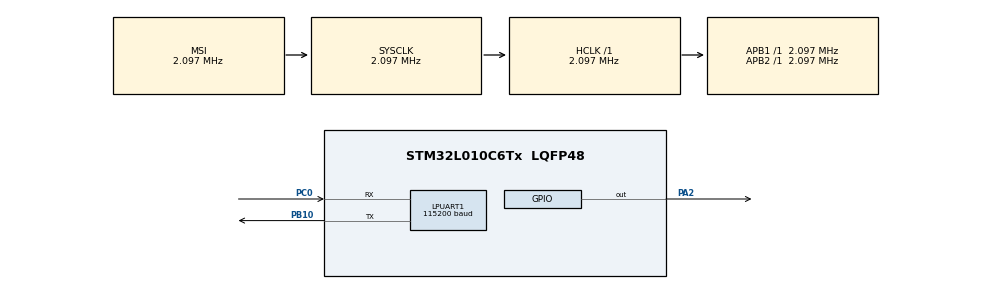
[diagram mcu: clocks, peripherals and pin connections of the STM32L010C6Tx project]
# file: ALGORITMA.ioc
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LPUART1.BaudRate=115200
LPUART1.WordLength=UART_WORDLENGTH_8B
Mcu.Family=STM32L0
Mcu.Name=STM32L010C6Tx
Mcu.Package=LQFP48
PA13.Mode=Serial_Wire
PA13.Signal=SYS_SWDIO
PA14.Mode=Serial_Wire
PA14.Signal=SYS_SWCLK
PA2.Signal=GPIO_Output
PB10.Mode=Asynchronous
PB10.Signal=LPUART1_TX
PC0.Mode=Asynchronous
PC0.Signal=LPUART1_RX
ProjectManager.HeapSize=0x200
ProjectManager.StackSize=0x400
ProjectManager.TargetToolchain=STM32CubeIDE
RCC.AHBFreq_Value=2097000
RCC.APB1Freq_Value=2097000
RCC.APB1TimFreq_Value=2097000
RCC.APB2Freq_Value=2097000
RCC.APB2TimFreq_Value=2097000
RCC.HSE_VALUE=8000000
RCC.HSI16_VALUE=16000000
RCC.HSI_VALUE=16000000
RCC.LSE_VALUE=32768
RCC.MSI_VALUE=2097000
RCC.SYSCLKFreq_VALUE=2097000
RCC.VCOOutputFreq_Value=48000000
board=custom

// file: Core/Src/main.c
/**
 @Adi: Zahide Zeynep
 @Soyadi: Kurt
 @Tarih: 11.05.2022
 @Ciktilar:
Örnek dizide çarpımları en büyük sonucu veren 13 ardışık rakam:
9x7x8x1x7x9x7x7x8x4x6x1x7= 2091059712 'dir.
Bu 13 rakamın  dizi içindeki konumu 504 ile başlayıp 516 ile bitmektedir

Örnek dizide çarpımları en büyük sonucu veren 14 ardışık rakam:
6x5x4x5x6x8x2x8x4x8x9x1x2x8= 2123366400 'dir.
Bu 14 rakamın  dizi içindeki konumu 723 ile başlayıp 736 ile bitmektedir

Örnek dizide çarpımları en büyük sonucu veren 15 ardışık rakam:
6x5x4x5x6x8x2x8x4x8x9x1x2x8x8= 2123366400 'dir.
Bu 15 rakamın  dizi içindeki konumu 723 ile başlayıp 737 ile bitmektedir
 ...
 */

/* USER CODE BEGIN Header */
/**
 ******************************************************************************
 * @file           : main.c
 * @brief          : Main program body
 ******************************************************************************
 * @attention
 *
 * <h2><center>&copy; Copyright (c) 2022 STMicroelectronics.
 * All rights reserved.</center></h2>
 *
 * This software component is licensed by ST under BSD 3-Clause license,
 * the "License"; You may not use this file except in compliance with the
 * License. You may obtain a copy of the License at:
 *                        opensource.org/licenses/BSD-3-Clause
 *
 ******************************************************************************
 */
/* USER CODE END Header */
#include "main.h"

/* USER CODE BEGIN Includes */
#include <string.h>
#include <stdio.h>
#include <stdlib.h>
#define printf(...)  HAL_UART_Transmit((UART_HandleTypeDef *)&hlpuart1, (uint8_t *)u_buf,\
		                                sprintf((char*)u_buf,__VA_ARGS__), 0xFFFF);
uint8_t u_buf[256];

/* USER CODE END Includes */

UART_HandleTypeDef hlpuart1;

void SystemClock_Config(void);
static void MX_GPIO_Init(void);
static void MX_LPUART1_UART_Init(void);

/* USER CODE BEGIN 0 */
#define ElemanSayisi 1000 //* Program herhangi bir X elemanlı herhangi bir diziye uygun olarak yazılmıştır. Buffer uzunluğunun her yerden kolayca değiştirilebilmesi için buffer uzunluğunu #define ile tanımlarız.
uint8_t buffer[ElemanSayisi] =
		{ 6, 4, 0, 7, 7, 1, 7, 6, 5, 3, 1, 3, 3, 0, 6, 2, 4, 9, 1, 9, 2, 2, 5,
				1, 1, 9, 6, 7, 4, 4, 2, 6, 5, 7, 4, 7, 4, 2, 3, 5, 5, 3, 4, 9,
				1, 9, 4, 9, 3, 4, 9, 6, 9, 8, 3, 5, 2, 0, 3, 1, 2, 7, 7, 4, 5,
				0, 6, 3, 2, 6, 2, 3, 9, 5, 7, 8, 3, 1, 8, 0, 1, 6, 9, 8, 4, 8,
				0, 1, 8, 6, 9, 4, 7, 8, 8, 5, 1, 8, 4, 3, 8, 5, 8, 6, 1, 5, 6,
				0, 7, 8, 9, 1, 1, 2, 9, 4, 9, 4, 9, 5, 4, 5, 9, 5, 0, 1, 7, 3,
				7, 9, 5, 8, 3, 3, 1, 9, 5, 2, 8, 5, 3, 2, 0, 8, 8, 0, 5, 5, 1,
				1, 1, 2, 5, 4, 0, 6, 9, 8, 7, 4, 7, 1, 5, 8, 5, 2, 3, 8, 6, 3,
				0, 5, 0, 7, 1, 5, 6, 9, 3, 2, 9, 0, 9, 6, 3, 2, 9, 5, 2, 2, 7,
				4, 4, 3, 0, 4, 3, 5, 5, 7, 6, 6, 8, 9, 6, 6, 4, 8, 9, 5, 0, 4,
				4, 5, 2, 4, 4, 5, 2, 3, 1, 6, 1, 7, 3, 1, 8, 5, 6, 4, 0, 3, 0,
				9, 8, 7, 1, 1, 1, 2, 1, 7, 2, 2, 3, 8, 3, 1, 1, 3, 6, 2, 2, 2,
				9, 8, 9, 3, 4, 2, 3, 3, 8, 0, 3, 0, 8, 1, 3, 5, 3, 3, 6, 2, 7,
				6, 6, 1, 4, 2, 8, 2, 8, 0, 6, 4, 4, 4, 4, 8, 6, 6, 4, 5, 2, 3,
				8, 7, 4, 9, 3, 0, 3, 5, 8, 9, 0, 7, 2, 9, 6, 2, 9, 0, 4, 9, 1,
				5, 6, 0, 4, 4, 0, 7, 7, 2, 3, 9, 0, 7, 1, 3, 8, 1, 0, 5, 1, 5,
				8, 5, 9, 3, 0, 7, 9, 6, 0, 8, 6, 6, 7, 0, 1, 7, 2, 4, 2, 7, 1,
				2, 1, 8, 8, 3, 9, 9, 8, 7, 9, 7, 9, 0, 8, 7, 9, 2, 2, 7, 4, 9,
				2, 1, 9, 0, 1, 6, 9, 9, 7, 2, 0, 8, 8, 8, 0, 9, 3, 7, 7, 6, 6,
				5, 7, 2, 7, 3, 3, 3, 0, 0, 1, 0, 5, 3, 3, 6, 7, 8, 8, 1, 2, 2,
				0, 2, 3, 5, 4, 2, 1, 8, 0, 9, 7, 5, 1, 2, 5, 4, 5, 4, 0, 5, 9,
				4, 7, 5, 2, 2, 4, 3, 5, 2, 5, 8, 4, 9, 0, 7, 7, 1, 1, 6, 7, 0,
				5, 5, 6, 0, 1, 3, 6, 0, 4, 8, 3, 9, 5, 8, 6, 4, 4, 6, 7, 0, 6,
				3, 2, 4, 4, 1, 5, 7, 2, 2, 1, 5, 5, 3, 9, 7, 5, 3, 6, 9, 7, 8,
				1, 7, 9, 7, 7, 8, 4, 6, 1, 7, 4, 0, 6, 4, 9, 5, 5, 1, 4, 9, 2,
				9, 0, 8, 6, 2, 5, 6, 9, 3, 2, 1, 9, 7, 8, 4, 6, 8, 6, 2, 2, 4,
				8, 2, 8, 3, 9, 7, 2, 2, 4, 1, 3, 7, 5, 6, 5, 7, 0, 5, 6, 0, 5,
				7, 4, 9, 0, 2, 6, 1, 4, 0, 7, 9, 7, 2, 9, 6, 8, 6, 5, 2, 4, 1,
				4, 5, 3, 5, 1, 0, 0, 4, 7, 4, 8, 2, 1, 6, 6, 3, 7, 0, 4, 8, 4,
				4, 0, 3, 1, 3, 9, 8, 9, 0, 0, 0, 8, 8, 9, 5, 2, 4, 3, 4, 5, 0,
				6, 5, 8, 5, 4, 1, 2, 2, 7, 5, 8, 8, 6, 6, 6, 8, 8, 1, 1, 6, 4,
				2, 7, 1, 7, 1, 4, 7, 9, 9, 2, 4, 4, 4, 2, 9, 2, 8, 2, 3, 0, 8,
				6, 3, 4, 6, 5, 6, 7, 4, 8, 1, 3, 9, 1, 9, 1, 2, 3, 1, 6, 2, 8,
				2, 4, 5, 8, 6, 1, 7, 8, 6, 6, 4, 5, 8, 3, 5, 9, 1, 2, 4, 5, 6,
				6, 5, 2, 9, 4, 7, 6, 5, 4, 5, 6, 8, 2, 8, 4, 8, 9, 1, 2, 8, 8,
				3, 1, 4, 2, 6, 0, 7, 6, 9, 0, 0, 4, 2, 2, 4, 2, 1, 9, 0, 2, 2,
				6, 7, 1, 0, 5, 5, 6, 2, 6, 3, 2, 1, 1, 1, 1, 1, 0, 9, 3, 7, 0,
				5, 4, 4, 2, 1, 7, 5, 0, 6, 9, 4, 1, 6, 5, 8, 9, 6, 0, 4, 0, 8,
				0, 7, 1, 9, 8, 4, 0, 3, 8, 5, 0, 9, 6, 2, 4, 5, 5, 4, 4, 4, 3,
				6, 2, 9, 8, 1, 2, 3, 0, 9, 8, 7, 8, 7, 9, 9, 2, 7, 2, 4, 4, 2,
				8, 4, 9, 0, 9, 1, 8, 8, 8, 4, 5, 8, 0, 1, 5, 6, 1, 6, 6, 0, 9,
				7, 9, 1, 9, 1, 3, 3, 8, 7, 5, 4, 9, 9, 2, 0, 0, 5, 2, 4, 0, 6,
				3, 6, 8, 9, 9, 1, 2, 5, 6, 0, 7, 1, 7, 6, 0, 6, 0, 5, 8, 8, 6,
				1, 1, 6, 4, 6, 7, 1, 0, 9, 4, 0, 5, 0, 7, 7, 5, 4, 1, 0, 0, 2,
				2, 5, 6, 9, 8, 3, 1, 5, 5, 2, 0, 0, 0, 5, 5, 9, 3, 5, 7, 2, 9,
				7, 2, 5, 7, 1, 6, 3, 6, 2, 6, 9, 5, 6, 1, 8, 8, 2, 6, 7, 0, 4,
				2, 8, 2, 5, 2, 4, 8, 3, 6, 0, 0, 8, 2, 3, 2, 5, 7, 5, 3, 0, 4,
				2, 0, 7, 5, 2, 9, 6, 3, 4, 5, 0, };

uint8_t *arr = (uint8_t*) &buffer; // Buffer adresini gösteren bir pointer arr oluşturduk.
// Program çıktısında istenilen çarpım sonucu ve başlangıç konumu tutacak global ifadeler tanımlanır.
int geciciIndex = 0, geciciCarpim = 0;
int Index, carpim, baslangic, bitis;
/* USER CODE END 0 */

int main(void) {

	/* MCU Configuration--------------------------------------------------------*/

	/* Reset of all peripherals, Initializes the Flash interface and the Systick. */
	HAL_Init();

	/* Configure the system clock */
	SystemClock_Config();

	/* Initialize all configured peripherals */
	MX_GPIO_Init();
	MX_LPUART1_UART_Init();
	int enbuyukcarpim(uint8_t *arr, int carpilacaksayi); //Aşağıda enbuyukcarpim adında bir fonksiyon oluşturulmuştur ve bu fonksiyon burada tanımlanır. Başındaki int, integer bir değer döndürdüğü anlamına gelir.
	int maxSayi = enbuyukcarpim(buffer, 13); //enbuyukcarpim foksiyonunun içine yukarıda tanılmış buffer ve kaç adet sayının çarpılmasını istiyorsak onu gönderiyoruz. burada fonksiyondan dönen sonucu MaxSayi içine atıyoruz.
	maxSayi = enbuyukcarpim(buffer, 14);
	maxSayi = enbuyukcarpim(buffer, 15);
	/* Infinite loop */
	while (1) {

	}
}

void SystemClock_Config(void) {
	RCC_OscInitTypeDef RCC_OscInitStruct = { 0 };
	RCC_ClkInitTypeDef RCC_ClkInitStruct = { 0 };
	RCC_PeriphCLKInitTypeDef PeriphClkInit = { 0 };

	/** Configure the main internal regulator output voltage
	 */
	__HAL_PWR_VOLTAGESCALING_CONFIG(PWR_REGULATOR_VOLTAGE_SCALE1);
	/** Initializes the RCC Oscillators according to the specified parameters
	 * in the RCC_OscInitTypeDef structure.
	 */
	RCC_OscInitStruct.OscillatorType = RCC_OSCILLATORTYPE_MSI;
	RCC_OscInitStruct.MSIState = RCC_MSI_ON;
	RCC_OscInitStruct.MSICalibrationValue = 0;
	RCC_OscInitStruct.MSIClockRange = RCC_MSIRANGE_5;
	RCC_OscInitStruct.PLL.PLLState = RCC_PLL_NONE;
	if (HAL_RCC_OscConfig(&RCC_OscInitStruct) != HAL_OK) {
		Error_Handler();
	}
	/** Initializes the CPU, AHB and APB buses clocks
	 */
	RCC_ClkInitStruct.ClockType = RCC_CLOCKTYPE_HCLK | RCC_CLOCKTYPE_SYSCLK
			| RCC_CLOCKTYPE_PCLK1 | RCC_CLOCKTYPE_PCLK2;
	RCC_ClkInitStruct.SYSCLKSource = RCC_SYSCLKSOURCE_MSI;
	RCC_ClkInitStruct.AHBCLKDivider = RCC_SYSCLK_DIV1;
	RCC_ClkInitStruct.APB1CLKDivider = RCC_HCLK_DIV1;
	RCC_ClkInitStruct.APB2CLKDivider = RCC_HCLK_DIV1;

	if (HAL_RCC_ClockConfig(&RCC_ClkInitStruct, FLASH_LATENCY_0) != HAL_OK) {
		Error_Handler();
	}
	PeriphClkInit.PeriphClockSelection = RCC_PERIPHCLK_LPUART1;
	PeriphClkInit.Lpuart1ClockSelection = RCC_LPUART1CLKSOURCE_PCLK1;
	if (HAL_RCCEx_PeriphCLKConfig(&PeriphClkInit) != HAL_OK) {
		Error_Handler();
	}
}

static void MX_LPUART1_UART_Init(void) {

	hlpuart1.Instance = LPUART1;
	hlpuart1.Init.BaudRate = 115200;
	hlpuart1.Init.WordLength = UART_WORDLENGTH_8B;
	hlpuart1.Init.StopBits = UART_STOPBITS_1;
	hlpuart1.Init.Parity = UART_PARITY_NONE;
	hlpuart1.Init.Mode = UART_MODE_TX_RX;
	hlpuart1.Init.HwFlowCtl = UART_HWCONTROL_NONE;
	hlpuart1.Init.OneBitSampling = UART_ONE_BIT_SAMPLE_DISABLE;
	hlpuart1.AdvancedInit.AdvFeatureInit = UART_ADVFEATURE_NO_INIT;
	if (HAL_UART_Init(&hlpuart1) != HAL_OK) {
		Error_Handler();
	}

}

static void MX_GPIO_Init(void) {
	GPIO_InitTypeDef GPIO_InitStruct = { 0 };

	/* GPIO Ports Clock Enable */
	__HAL_RCC_GPIOC_CLK_ENABLE();
	__HAL_RCC_GPIOA_CLK_ENABLE();
	__HAL_RCC_GPIOB_CLK_ENABLE();

	/*Configure GPIO pin Output Level */
	HAL_GPIO_WritePin(GPIOA, GPIO_PIN_2, GPIO_PIN_RESET);

	/*Configure GPIO pin : PA2 */
	GPIO_InitStruct.Pin = GPIO_PIN_2;
	GPIO_InitStruct.Mode = GPIO_MODE_OUTPUT_PP;
	GPIO_InitStruct.Pull = GPIO_NOPULL;
	GPIO_InitStruct.Speed = GPIO_SPEED_FREQ_LOW;
	HAL_GPIO_Init(GPIOA, &GPIO_InitStruct);

}

/* USER CODE BEGIN 4 */
/*
 * uint8_t *arr ifadesi buffer adresini gösterir.
 * int carpilacaksayi çarpıldığında en büyük sonucu veren sayı adetini gösterir.
 * Mülakat sorusunda 15 ardışık sayıya kadar hesaplayabilmeli denildiği için 15'ten büyük bir sayı girildiğinde "1 ile 15" arasında sayı istenmektedir.
 *
 */
int enbuyukcarpim(uint8_t *arr, int carpilacaksayi) {
	if (0 < carpilacaksayi && carpilacaksayi <= 15) {

		for (int j = 0; j < ElemanSayisi; j++) { //* Program herhangi bir X elemanlı herhangi bir diziye uygun olarak yazılmıştır. Yukarıda ElemanSayisi değiştirildiğinden otomatikman değişir.

			//carpilacaksayi: fonksiyonda belirtilen çarpım adetini belirtmektedir. 0. index'ten başlayarak kaç adet sayının çarpılması gerekiyor ise o kadar sayı çarpılır ve geciciCarpim 'da tutulur.
			geciciCarpim = arr[j];
			for (int m = 1; m < carpilacaksayi; m++) {
				geciciCarpim = geciciCarpim * arr[j + m];
			}

			geciciIndex = j;

			//carpim default olarak 0 belirlenir. geciciCarpim carpim'dan büyük olduğunda bu ifade carpimin içine yazılır. Bu sayede en büyük çarpım carpim ifadesinin içinde tuutlmuş olur. Aynı şekilde Index'te tutulmuş olur.
			if (geciciCarpim > carpim) {
				carpim = geciciCarpim;
				Index = geciciIndex;
			}

		}
		// Ve Aşağıda istenilen formatta çıktı yazılır.
		printf("Örnek dizide çarpımları en büyük sonucu veren %d ardışık rakam: \n",carpilacaksayi);
		for (int m = 0; m < carpilacaksayi; m++) {
			printf("%.1d", arr[Index + m]);
			if ((carpilacaksayi - 1) != m) { //son rakama kadar araya çarpım ifadesi konulur. Örneğin: 9x9x8x7
				printf("x");
			}
		}

		printf("= %.1d 'dir. \r \n", carpim);
		printf("Bu %d rakamın  dizi içindeki konumu %d ile başlayıp %d ile bitmektedir ", carpilacaksayi, (Index + 1), (Index + carpilacaksayi));

		printf("\n\n");
		return carpim;
	} else { //1 ile 15 arasında bir sayı girilmezse uyarı verir.
		printf("Lütfen 1 ile 15 arasinda bir sayi giriniz.");
		return 0;
	}

}
/* USER CODE END 4 */

void Error_Handler(void) {
	__disable_irq();
	while (1) {
	}
}

/************************ (C) COPYRIGHT STMicroelectronics *****END OF FILE****/
